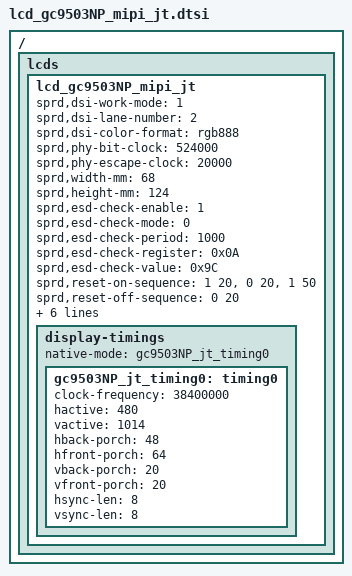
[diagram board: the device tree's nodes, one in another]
/ {
	fragment {
		target-path = "/";
		__overlay__ {
			lcds {
				lcd_gc9503NP_mipi_jt: lcd_gc9503NP_mipi_jt {

					sprd,dsi-work-mode = <1>;
					sprd,dsi-lane-number = <2>;
					sprd,dsi-color-format = "rgb888";

					sprd,phy-bit-clock = <524000>;
					sprd,phy-escape-clock = <20000>;

					sprd,width-mm = <68>;
					sprd,height-mm = <124>;

					sprd,esd-check-enable = <1>;
					sprd,esd-check-mode = <0>;
					sprd,esd-check-period = <1000>;
					sprd,esd-check-register = <0x0A>;
					sprd,esd-check-value = <0x9C>;

					sprd,reset-on-sequence = <1 20>, <0 20>, <1 50>;
					sprd,reset-off-sequence = <0 20>;

					sprd,initial-command = [
						39 00 00 06 F0 55 AA 52 08 00
						39 00 00 03 F6 5A 87
						23 00 00 02 C1 3F
						23 00 00 02 C2 07
						23 00 00 02 C6 F8
						23 00 00 02 C9 10
						23 00 00 02 CD 25
						39 00 00 05 86 99 A3 A3 41
						39 00 00 04 87 04 03 66
						23 00 00 02 F8 8A
						23 00 00 02 AC 45
						23 00 00 02 A7 47
						23 00 00 02 A0 99
						39 00 00 05 FA 03 03 00 04
						23 00 00 02 A3 6A
						39 00 00 04 FD 28 3C 00
						23 00 00 02 9A 73
						23 00 00 02 9B 24
						39 00 00 03 82 13 13
						23 00 00 02 B1 10
						39 00 00 03 7A 13 1A
						39 00 00 03 7B 13 1A
						39 00 00 21 6D 1F 03 02 08 1E 00 1D 0E 10 0A 0C 1E 1E 1E 1E 1E 1E 1E 1E 1E 1E 0B 09 0F 0D 1D 00 1E 07 01 03 1F
						39 00 00 09 60 38 0D 2E 7A 38 0C 2E 7A
						39 00 00 09 61 F4 07 7A 7A 38 09 7A 7A
						39 00 00 09 62 38 09 7A 7A F4 07 7A 7A
						39 00 00 09 63 38 0B 2E 7A 38 0A 2E 7A
						39 00 00 11 64 38 0A 03 F6 03 03 38 09 03 F7 03 03 2E 7A 2E 7A
						39 00 00 11 65 38 08 03 F8 03 03 38 07 03 F9 03 03 2E 7A 2E 7A
						39 00 00 11 66 38 06 03 FA 03 03 38 05 03 FB 03 03 2E 7A 2E 7A
						39 00 00 11 67 38 04 03 FC 03 03 38 03 03 FD 03 03 2E 7A 2E 7A
						39 00 00 08 69 14 22 14 22 44 22 08
						23 00 00 02 6B 07
						39 00 00 35 D1 00 00 00 2E 00 67 00 90 00 B0 00 E2 01 0A 01 49 01 7C 01 CB 02 09 02 67 02 B0 02 B2 02 F2 03 33 03 5B 03 91 03 A8 03 BC 03 C9 03 DA 03 E5 03 F0 03 FA 03 FF
						39 00 00 35 D2 00 00 00 2E 00 67 00 90 00 B0 00 E2 01 0A 01 49 01 7C 01 CB 02 09 02 67 02 B0 02 B2 02 F2 03 33 03 5B 03 91 03 A8 03 BC 03 C9 03 DA 03 E5 03 F0 03 FA 03 FF
						39 00 00 35 D3 00 00 00 2E 00 67 00 90 00 B0 00 E2 01 0A 01 49 01 7C 01 CB 02 09 02 67 02 B0 02 B2 02 F2 03 33 03 5B 03 91 03 A8 03 BC 03 C9 03 DA 03 E5 03 F0 03 FA 03 FF
						39 00 00 35 D4 00 00 00 2E 00 67 00 90 00 B0 00 E2 01 0A 01 49 01 7C 01 CB 02 09 02 67 02 B0 02 B2 02 F2 03 33 03 5B 03 91 03 A8 03 BC 03 C9 03 DA 03 E5 03 F0 03 FA 03 FF
						39 00 00 35 D5 00 00 00 2E 00 67 00 90 00 B0 00 E2 01 0A 01 49 01 7C 01 CB 02 09 02 67 02 B0 02 B2 02 F2 03 33 03 5B 03 91 03 A8 03 BC 03 C9 03 DA 03 E5 03 F0 03 FA 03 FF
						39 00 00 35 D6 00 00 00 2E 00 67 00 90 00 B0 00 E2 01 0A 01 49 01 7C 01 CB 02 09 02 67 02 B0 02 B2 02 F2 03 33 03 5B 03 91 03 A8 03 BC 03 C9 03 DA 03 E5 03 F0 03 FA 03 FF
						23 78 00 02 11 00
						23 14 00 02 29 00
						];
					sprd,sleep-in-command = [
						23 14 00 02 6C 60
						23 00 00 02 B1 00
						39 14 00 05 FA 7F 00 00 00
						23 0a 00 02 6c 50
						23 32 00 02 28 00
						23 78 00 02 10 00
						39 00 00 06 F0 55 aa 52 08 00
						23 00 00 02 c2 ce
						23 00 00 02 c3 cd
						23 00 00 02 c6 fc
						23 00 00 02 c5 03
						23 00 00 02 cd 64
						23 00 00 02 c4 ff
						23 00 00 02 c9 cd
						39 00 00 03 F6 5a 87
						39 00 00 04 Fd aa aa 0a
						39 00 00 03 Fe 6a 0a
						39 00 00 03 78 2a aa
						39 00 00 03 92 17 08
						39 00 00 03 77 aa 2a
						39 00 00 03 76 aa aa
						23 00 00 02 84 00
						39 00 00 03 78 2b ba
						23 00 00 02 89 73
						23 00 00 02 88 3A
						23 00 00 02 85 B0
						39 00 00 03 76 eb aa
						23 00 00 02 94 80
						39 00 00 04 87 04 07 30
						23 00 00 02 93 27
						23 00 00 02 af 02
						];
					sprd,sleep-out-command = [
						13 78 00 01 11
						13 64 00 01 29
						];

					display-timings {
						native-mode = <&gc9503NP_jt_timing0>;

						gc9503NP_jt_timing0: timing0 {
							clock-frequency = <38400000>;
							hactive = <480>;
							vactive = <1014>;
							hback-porch = <48>;
							hfront-porch = <64>;
							vback-porch = <20>;
							vfront-porch = <20>;
							hsync-len = <8>;
							vsync-len = <8>;
						};
					};
				};
			};
		};
	};
};
